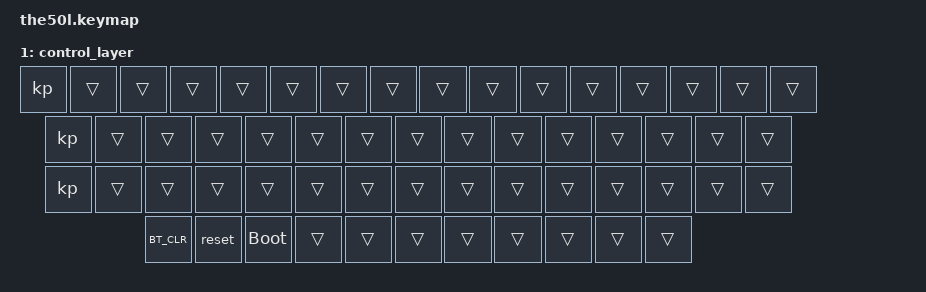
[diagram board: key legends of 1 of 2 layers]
/*
 * Copyright (c) 2023 LAZYDESIGNERS
 *
 * SPDX-License-Identifier: MIT
 */

#include <behaviors.dtsi>
#include <dt-bindings/zmk/keys.h>
#include <dt-bindings/zmk/bt.h>
#include <dt-bindings/zmk/outputs.h>


/ {
	keymap {
		compatible = "zmk,keymap";
		
default_layer {
// ---------------------------------------------------------------------------------------------
// | 7  |  8  |  9  | ESC |  Q  |  W  |  E  |  R  |  T  |  Y  |  U  |  I  |  O  |  P  |  BSPC  |
// | 4  |  5  |  6  | TAB  |  A  |  S  |  D  |  F  |  G  |  H  |  J  |  K  |  L  |    ENTER    |
// | 1  |  2  |  3  | SHIFT  |  Z  |  X  |  C  |  V  |  B  |  N  |  M  |  ,  |  UP  |  SHIFT   |
// | 0  |  .  |ENTER| CTL  |  WIN  |  ALT  |    SPACE   |    SPACE   |  LEFT | DOWN  |  RIGHT  |
// ---------------------------------------------------------------------------------------------
			bindings = <
	&kp N7  &kp N8  &kp N9     &gresc  &kp Q  &kp W  &kp E  &kp R  &kp T  &kp Y  &kp U  &kp I  &kp O  &kp P      &kp BSPC
	&kp N4  &kp N5  &kp N6     &kp TAB   &kp A  &kp S  &kp D  &kp F  &kp G  &kp H  &kp J  &kp K  &kp L     &kp RET
	&kp N1  &kp N2  &kp N3     &kp LSHFT   &kp Z  &kp X  &kp C  &kp V  &kp B  &kp N  &kp M  &kp COMMA &kp UP     &kp RSHFT
	&kp N0  &kp DOT &kp RET    &kp LCTRL &kp LGUI &kp LALT  &kp SPACE          &mo 1     &kp RGUI   &kp RCTRL    &kp RCTRL
			>;
		};

control_layer  {
// ---------------------------------------------------------------------------------------------
// | 7  |  8  |  9  | ESC |  Q  |  W  |  E  |  R  |  T  |  Y  |  U  |  I  |  O  |  P  |  BSPC  |
// | 4  |  5  |  6  | TAB  |  A  |  S  |  D  |  F  |  G  |  H  |  J  |  K  |  L  |    ENTER    |
// | 1  |  2  |  3  | SHIFT  |  Z  |  X  |  C  |  V  |  B  |  N  |  M  |  ,  |  UP  |  SHIFT   |
// | 0  |  .  |ENTER| CTL  |  WIN  |  ALT  |    SPACE   |    SPACE   |  LEFT | DOWN  |  RIGHT  |
// ---------------------------------------------------------------------------------------------

			bindings = <
	&kp &trans  &trans  &trans      &trans  &trans  &trans  &trans  &trans  &trans  &trans  &trans  &trans  &trans &trans     &trans
	&kp &trans  &trans  &trans      &trans   &trans  &trans  &trans    &trans   &trans   &trans   &trans  &trans  &trans   &trans
	&kp &trans  &trans  &trans      &trans  &trans  &trans  &trans   &trans   &trans      &trans     &trans   &trans   &trans   &trans
	&kp BT_CLR  &reset &bootloader  &trans  &trans  &trans       &trans                      &trans           &trans   &trans   &trans
			>;
		};
	};
};
